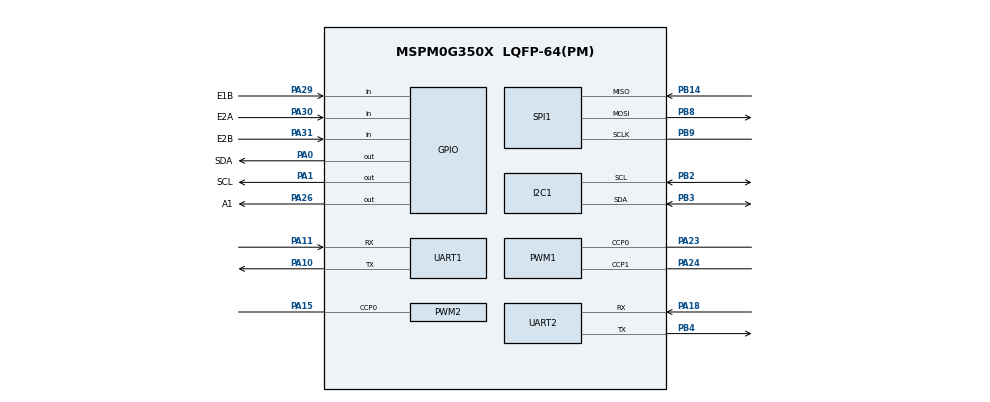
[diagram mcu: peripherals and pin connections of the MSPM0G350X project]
/**
 * These arguments were used when this file was generated. They will be automatically applied on subsequent loads
 * via the GUI or CLI. Run CLI with '--help' for additional information on how to override these arguments.
 * @cliArgs --device "MSPM0G350X" --package "LQFP-64(PM)" --part "Default" --product "mspm0_sdk@2.01.00.03"
 * @versions {"tool":"1.19.0+3426"}
 */

/**
 * Import the modules used in this configuration.
 */
const GPIO          = scripting.addModule("/ti/driverlib/GPIO", {}, false);
const GPIO1         = GPIO.addInstance();
const GPIO2         = GPIO.addInstance();
const GPIO3         = GPIO.addInstance();
const GPIO4         = GPIO.addInstance();
const GPIO5         = GPIO.addInstance();
const I2C           = scripting.addModule("/ti/driverlib/I2C", {}, false);
const I2C1          = I2C.addInstance();
const PWM           = scripting.addModule("/ti/driverlib/PWM", {}, false);
const PWM1          = PWM.addInstance();
const PWM2          = PWM.addInstance();
const SPI           = scripting.addModule("/ti/driverlib/SPI", {}, false);
const SPI1          = SPI.addInstance();
const SYSCTL        = scripting.addModule("/ti/driverlib/SYSCTL");
const TIMER         = scripting.addModule("/ti/driverlib/TIMER", {}, false);
const TIMER1        = TIMER.addInstance();
const UART          = scripting.addModule("/ti/driverlib/UART", {}, false);
const UART1         = UART.addInstance();
const UART2         = UART.addInstance();
const ProjectConfig = scripting.addModule("/ti/project_config/ProjectConfig");

/**
 * Write custom configuration values to the imported modules.
 */
const divider7       = system.clockTree["PLL_PDIV"];
divider7.divideValue = 4;

const divider9       = system.clockTree["UDIV"];
divider9.divideValue = 2;

const gate7  = system.clockTree["MFCLKGATE"];
gate7.enable = true;

const gate8  = system.clockTree["MFPCLKGATE"];
gate8.enable = true;

const multiplier2         = system.clockTree["PLL_QDIV"];
multiplier2.multiplyValue = 9;

const mux8       = system.clockTree["HSCLKMUX"];
mux8.inputSelect = "HSCLKMUX_SYSPLL2X";

GPIO1.$name                                       = "ENCODER_A";
GPIO1.port                                        = "PORTA";
GPIO1.associatedPins.create(2);
GPIO1.associatedPins[0].$name                     = "E1A";
GPIO1.associatedPins[0].direction                 = "INPUT";
GPIO1.associatedPins[0].interruptEn               = true;
GPIO1.associatedPins[0].polarity                  = "RISE";
GPIO1.associatedPins[0].assignedPin               = "28";
GPIO1.associatedPins[0].pin.$assignAllowConflicts = "PA28";
GPIO1.associatedPins[1].$name                     = "E1B";
GPIO1.associatedPins[1].direction                 = "INPUT";
GPIO1.associatedPins[1].interruptEn               = true;
GPIO1.associatedPins[1].polarity                  = "RISE";
GPIO1.associatedPins[1].assignedPin               = "29";
GPIO1.associatedPins[1].pin.$assign               = "PA29";

const Board = scripting.addModule("/ti/driverlib/Board", {}, false);

GPIO2.$name                         = "ENCODER_B";
GPIO2.port                          = "PORTA";
GPIO2.associatedPins.create(2);
GPIO2.associatedPins[0].$name       = "E2A";
GPIO2.associatedPins[0].direction   = "INPUT";
GPIO2.associatedPins[0].interruptEn = true;
GPIO2.associatedPins[0].polarity    = "RISE";
GPIO2.associatedPins[0].assignedPin = "30";
GPIO2.associatedPins[0].pin.$assign = "PA30";
GPIO2.associatedPins[1].$name       = "E2B";
GPIO2.associatedPins[1].direction   = "INPUT";
GPIO2.associatedPins[1].interruptEn = true;
GPIO2.associatedPins[1].polarity    = "RISE";
GPIO2.associatedPins[1].assignedPin = "31";
GPIO2.associatedPins[1].pin.$assign = "PA31";

GPIO3.$name                              = "TFT";
GPIO3.associatedPins.create(2);
GPIO3.associatedPins[0].$name            = "RESET";
GPIO3.associatedPins[0].assignedPort     = "PORTB";
GPIO3.associatedPins[0].internalResistor = "PULL_UP";
GPIO3.associatedPins[0].assignedPin      = "0";
GPIO3.associatedPins[1].$name            = "DC_RS";
GPIO3.associatedPins[1].internalResistor = "PULL_UP";
GPIO3.associatedPins[1].assignedPin      = "2";
GPIO3.associatedPins[1].assignedPort     = "PORTA";

GPIO4.$name                          = "MPU6050";
GPIO4.associatedPins.create(2);
GPIO4.associatedPins[0].$name        = "SDA";
GPIO4.associatedPins[0].assignedPort = "PORTA";
GPIO4.associatedPins[0].ioStructure  = "OD";
GPIO4.associatedPins[0].pin.$assign  = "PA0";
GPIO4.associatedPins[1].$name        = "SCL";
GPIO4.associatedPins[1].assignedPort = "PORTA";
GPIO4.associatedPins[1].ioStructure  = "OD";
GPIO4.associatedPins[1].pin.$assign  = "PA1";

GPIO5.$name                          = "MOTOR_DIR";
GPIO5.associatedPins.create(4);
GPIO5.associatedPins[0].$name        = "A1";
GPIO5.associatedPins[0].assignedPort = "PORTA";
GPIO5.associatedPins[0].assignedPin  = "26";
GPIO5.associatedPins[0].pin.$assign  = "PA26";
GPIO5.associatedPins[1].$name        = "A2";
GPIO5.associatedPins[1].assignedPort = "PORTA";
GPIO5.associatedPins[1].assignedPin  = "27";
GPIO5.associatedPins[1].initialValue = "SET";
GPIO5.associatedPins[2].$name        = "B1";
GPIO5.associatedPins[2].assignedPort = "PORTB";
GPIO5.associatedPins[2].assignedPin  = "26";
GPIO5.associatedPins[3].$name        = "B2";
GPIO5.associatedPins[3].assignedPort = "PORTB";
GPIO5.associatedPins[3].assignedPin  = "27";
GPIO5.associatedPins[3].initialValue = "SET";

I2C1.$name                             = "I2C_MPU6050";
I2C1.basicEnableController             = true;
I2C1.intController                     = ["ARBITRATION_LOST","NACK","RXFIFO_TRIGGER","RX_DONE","TX_DONE"];
I2C1.peripheral.$assign                = "I2C1";
I2C1.peripheral.sdaPin.$assign         = "PB3";
I2C1.peripheral.sclPin.$assign         = "PB2";
I2C1.sdaPinConfig.hideOutputInversion  = scripting.forceWrite(false);
I2C1.sdaPinConfig.onlyInternalResistor = scripting.forceWrite(false);
I2C1.sdaPinConfig.passedPeripheralType = scripting.forceWrite("Digital");
I2C1.sdaPinConfig.$name                = "ti_driverlib_gpio_GPIOPinGeneric8";
I2C1.sclPinConfig.hideOutputInversion  = scripting.forceWrite(false);
I2C1.sclPinConfig.onlyInternalResistor = scripting.forceWrite(false);
I2C1.sclPinConfig.passedPeripheralType = scripting.forceWrite("Digital");
I2C1.sclPinConfig.$name                = "ti_driverlib_gpio_GPIOPinGeneric9";

PWM1.$name                              = "PWM_MOTOR";
PWM1.pwmMode                            = "EDGE_ALIGN_UP";
PWM1.clockPrescale                      = 36;
PWM1.peripheral.$assign                 = "TIMG0";
PWM1.peripheral.ccp0Pin.$assign         = "PA23";
PWM1.peripheral.ccp1Pin.$assign         = "PA24";
PWM1.PWM_CHANNEL_0.$name                = "ti_driverlib_pwm_PWMTimerCC0";
PWM1.PWM_CHANNEL_0.ccValue              = 1000;
PWM1.PWM_CHANNEL_1.$name                = "ti_driverlib_pwm_PWMTimerCC1";
PWM1.PWM_CHANNEL_1.ccValue              = 1000;
PWM1.ccp0PinConfig.$name                = "ti_driverlib_gpio_GPIOPinGeneric2";
PWM1.ccp0PinConfig.direction            = scripting.forceWrite("OUTPUT");
PWM1.ccp0PinConfig.hideOutputInversion  = scripting.forceWrite(false);
PWM1.ccp0PinConfig.onlyInternalResistor = scripting.forceWrite(false);
PWM1.ccp0PinConfig.passedPeripheralType = scripting.forceWrite("Digital");
PWM1.ccp1PinConfig.$name                = "ti_driverlib_gpio_GPIOPinGeneric3";
PWM1.ccp1PinConfig.direction            = scripting.forceWrite("OUTPUT");
PWM1.ccp1PinConfig.hideOutputInversion  = scripting.forceWrite(false);
PWM1.ccp1PinConfig.onlyInternalResistor = scripting.forceWrite(false);
PWM1.ccp1PinConfig.passedPeripheralType = scripting.forceWrite("Digital");

PWM2.$name                              = "PWM_SERVO";
PWM2.clockPrescale                      = 144;
PWM2.timerCount                         = 10000;
PWM2.pwmMode                            = "EDGE_ALIGN_UP";
PWM2.ccIndex                            = [0];
PWM2.timerStartTimer                    = true;
PWM2.peripheral.$assign                 = "TIMA1";
PWM2.peripheral.ccp0Pin.$assign         = "PA15";
PWM2.PWM_CHANNEL_0.$name                = "ti_driverlib_pwm_PWMTimerCC2";
PWM2.PWM_CHANNEL_0.ccValue              = 1000;
PWM2.ccp0PinConfig.direction            = scripting.forceWrite("OUTPUT");
PWM2.ccp0PinConfig.hideOutputInversion  = scripting.forceWrite(false);
PWM2.ccp0PinConfig.onlyInternalResistor = scripting.forceWrite(false);
PWM2.ccp0PinConfig.passedPeripheralType = scripting.forceWrite("Digital");
PWM2.ccp0PinConfig.$name                = "ti_driverlib_gpio_GPIOPinGeneric7";

SPI1.frameFormat                        = "MOTO3";
SPI1.$name                              = "HARDSPI_TFT";
SPI1.targetBitRate                      = 16000000;
SPI1.peripheral.$assign                 = "SPI1";
SPI1.peripheral.sclkPin.$assign         = "PB9";
SPI1.peripheral.mosiPin.$assign         = "PB8";
SPI1.peripheral.misoPin.$assign         = "PB14";
SPI1.sclkPinConfig.direction            = scripting.forceWrite("OUTPUT");
SPI1.sclkPinConfig.onlyInternalResistor = scripting.forceWrite(false);
SPI1.sclkPinConfig.passedPeripheralType = scripting.forceWrite("Digital");
SPI1.sclkPinConfig.$name                = "ti_driverlib_gpio_GPIOPinGeneric4";
SPI1.sclkPinConfig.enableConfig         = true;
SPI1.sclkPinConfig.internalResistor     = "PULL_UP";
SPI1.mosiPinConfig.direction            = scripting.forceWrite("OUTPUT");
SPI1.mosiPinConfig.hideOutputInversion  = scripting.forceWrite(false);
SPI1.mosiPinConfig.onlyInternalResistor = scripting.forceWrite(false);
SPI1.mosiPinConfig.passedPeripheralType = scripting.forceWrite("Digital");
SPI1.mosiPinConfig.$name                = "ti_driverlib_gpio_GPIOPinGeneric5";
SPI1.misoPinConfig.onlyInternalResistor = scripting.forceWrite(false);
SPI1.misoPinConfig.passedPeripheralType = scripting.forceWrite("Digital");
SPI1.misoPinConfig.$name                = "ti_driverlib_gpio_GPIOPinGeneric6";
SPI1.misoPinConfig.enableConfig         = true;
SPI1.misoPinConfig.internalResistor     = "PULL_UP";

SYSCTL.clockTreeEn = true;

TIMER1.$name            = "TIMER_0";
TIMER1.interrupts       = ["ZERO"];
TIMER1.timerClkDiv      = 8;
TIMER1.timerMode        = "PERIODIC_UP";
TIMER1.timerStartTimer  = true;
TIMER1.timerPeriod      = "10 ms";
TIMER1.timerClkPrescale = 90;

UART1.$name                    = "UART_0";
UART1.enableFIFO               = true;
UART1.rxFifoThreshold          = "DL_UART_RX_FIFO_LEVEL_ONE_ENTRY";
UART1.enableInternalLoopback   = true;
UART1.enableDMARX              = false;
UART1.enableDMATX              = false;
UART1.peripheral.$assign       = "UART0";
UART1.peripheral.rxPin.$assign = "PA11";
UART1.peripheral.txPin.$assign = "PA10";
UART1.txPinConfig.$name        = "ti_driverlib_gpio_GPIOPinGeneric0";
UART1.rxPinConfig.$name        = "ti_driverlib_gpio_GPIOPinGeneric1";

UART2.$name                            = "UART_OPENMV";
UART2.enabledInterrupts                = ["RX"];
UART2.peripheral.$assign               = "UART1";
UART2.peripheral.rxPin.$assign         = "PA18";
UART2.peripheral.txPin.$assign         = "PB4";
UART2.txPinConfig.direction            = scripting.forceWrite("OUTPUT");
UART2.txPinConfig.hideOutputInversion  = scripting.forceWrite(false);
UART2.txPinConfig.onlyInternalResistor = scripting.forceWrite(false);
UART2.txPinConfig.passedPeripheralType = scripting.forceWrite("Digital");
UART2.txPinConfig.$name                = "ti_driverlib_gpio_GPIOPinGeneric10";
UART2.rxPinConfig.hideOutputInversion  = scripting.forceWrite(false);
UART2.rxPinConfig.onlyInternalResistor = scripting.forceWrite(false);
UART2.rxPinConfig.passedPeripheralType = scripting.forceWrite("Digital");
UART2.rxPinConfig.$name                = "ti_driverlib_gpio_GPIOPinGeneric11";

ProjectConfig.deviceSpin = "MSPM0G3507";

/**
 * Pinmux solution for unlocked pins/peripherals. This ensures that minor changes to the automatic solver in a future
 * version of the tool will not impact the pinmux you originally saw.  These lines can be completely deleted in order to
 * re-solve from scratch.
 */
Board.peripheral.$suggestSolution            = "DEBUGSS";
Board.peripheral.swclkPin.$suggestSolution   = "PA20";
Board.peripheral.swdioPin.$suggestSolution   = "PA19";
GPIO3.associatedPins[0].pin.$suggestSolution = "PB0";
GPIO3.associatedPins[1].pin.$suggestSolution = "PA2";
GPIO5.associatedPins[1].pin.$suggestSolution = "PA27";
GPIO5.associatedPins[2].pin.$suggestSolution = "PB26";
GPIO5.associatedPins[3].pin.$suggestSolution = "PB27";
TIMER1.peripheral.$suggestSolution           = "TIMA0";
